VERSION "0.1"

NS_ :

BS_ :

BU_ : bms_lv dash dspace sens_front sens_rear tlb_bat

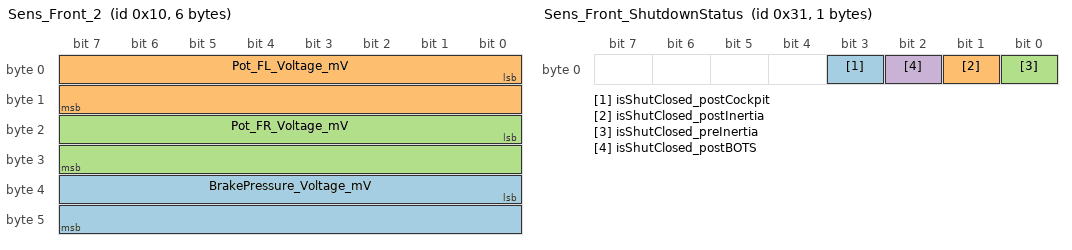
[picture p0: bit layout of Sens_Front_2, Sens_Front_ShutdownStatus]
BO_ 16 Sens_Front_2: 6 Vector__XXX
	SG_ BrakePressure_Voltage_mV : 32|16@1+ (1,0) [0|65535] "" Vector__XXX
	SG_ Pot_FL_Voltage_mV : 0|16@1+ (1,0) [0|65535] "" Vector__XXX
	SG_ Pot_FR_Voltage_mV : 16|16@1+ (1,0) [0|65535] "" Vector__XXX

BO_ 49 Sens_Front_ShutdownStatus: 1 Vector__XXX
	SG_ isShutClosed_postCockpit : 3|1@1- (1,0) [0|1] "" Vector__XXX
	SG_ isShutClosed_postInertia : 1|1@1- (1,0) [0|1] "" Vector__XXX
	SG_ isShutClosed_preInertia : 0|1@1- (1,0) [0|1] "" Vector__XXX
	SG_ isShutClosed_postBOTS : 2|1@1- (1,0) [0|1] "" Vector__XXX

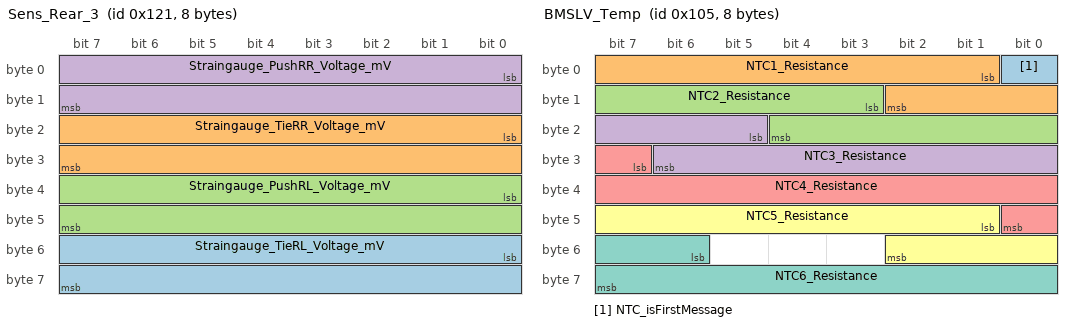
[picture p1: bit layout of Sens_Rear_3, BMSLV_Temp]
BO_ 289 Sens_Rear_3: 8 Vector__XXX
	SG_ Straingauge_TieRL_Voltage_mV : 48|16@1+ (1,0) [0|65535] "" Vector__XXX
	SG_ Straingauge_TieRR_Voltage_mV : 16|16@1+ (1,0) [0|65535] "" Vector__XXX
	SG_ Straingauge_PushRL_Voltage_mV : 32|16@1+ (1,0) [0|65535] "" Vector__XXX
	SG_ Straingauge_PushRR_Voltage_mV : 0|16@1+ (1,0) [0|65535] "" Vector__XXX

BO_ 258 BMSLV_BatteryPackGeneral: 4 Vector__XXX
	SG_ Current_Sensor_Voltage : 0|16@1+ (0.076,0) [0|4980.66] "" Vector__XXX
	SG_ LV_Total_Voltage_mV : 16|16@1+ (0.267,14000) [14000|31497.8] "" Vector__XXX

BO_ 261 BMSLV_Temp: 8 Vector__XXX
	SG_ NTC_isFirstMessage : 0|1@1- (1,0) [0|1] "" Vector__XXX
	SG_ NTC1_Resistance : 1|10@1+ (31.25,1000) [1000|32968.8] "" Vector__XXX
	SG_ NTC2_Resistance : 11|10@1+ (31.25,1000) [1000|32968.8] "" Vector__XXX
	SG_ NTC3_Resistance : 21|10@1+ (31.25,1000) [1000|32968.8] "" Vector__XXX
	SG_ NTC4_Resistance : 31|10@1+ (31.25,1000) [1000|32968.8] "" Vector__XXX
	SG_ NTC5_Resistance : 41|10@1+ (31.25,1000) [1000|32968.8] "" Vector__XXX
	SG_ NTC6_Resistance : 54|10@1+ (31.25,1000) [1000|32968.8] "" Vector__XXX

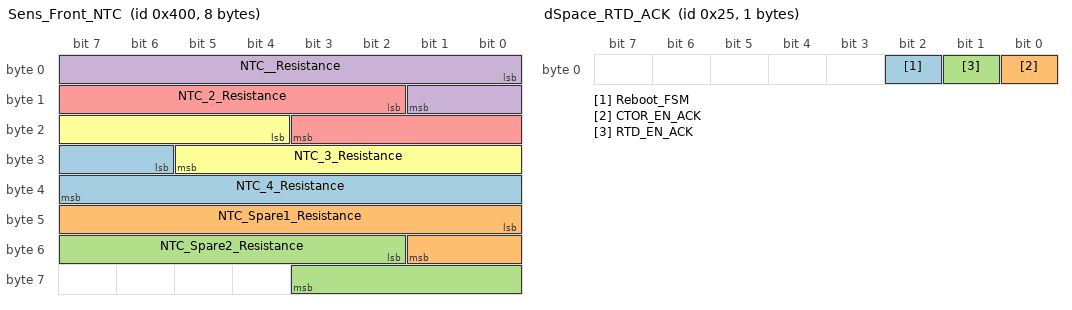
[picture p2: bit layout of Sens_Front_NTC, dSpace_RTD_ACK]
BO_ 1024 Sens_Front_NTC: 8 Vector__XXX
	SG_ NTC_4_Resistance : 30|10@1+ (1,0) [0|1023] "" Vector__XXX
	SG_ NTC_Spare1_Resistance : 40|10@1+ (1,0) [0|1023] "" Vector__XXX
	SG_ NTC_Spare2_Resistance : 50|10@1+ (1,0) [0|1023] "" Vector__XXX
	SG_ NTC__Resistance : 0|10@1+ (1,0) [0|1023] "" Vector__XXX
	SG_ NTC_2_Resistance : 10|10@1+ (1,0) [0|1023] "" Vector__XXX
	SG_ NTC_3_Resistance : 20|10@1+ (1,0) [0|1023] "" Vector__XXX

BO_ 38 Steering_RTD: 1 Vector__XXX
	SG_ RTD_CMD : 0|8@1+ (1,0) [0|255] "" Vector__XXX

BO_ 37 dSpace_RTD_ACK: 1 Vector__XXX
	SG_ Reboot_FSM : 2|1@1- (1,0) [0|1] "" Vector__XXX
	SG_ CTOR_EN_ACK : 0|1@1- (1,0) [0|1] "" Vector__XXX
	SG_ RTD_EN_ACK : 1|1@1- (1,0) [0|1] "" Vector__XXX

BO_ 259 BMSLV_Status: 2 Vector__XXX
	SG_ isRelayOpen : 0|1@1- (1,0) [0|1] "" Vector__XXX
	SG_ BMSLV_StatusMessage : 1|8@1+ (1,0) [0|255] "" Vector__XXX

BO_ 70 TlbBatIntSig: 8 tlb_bat
	SG_ DcBusPrchRlyEnAuxState : 24|2@1+ (1,0) [0|1] "" dspace
	SG_ DcBusVehSideOver60VImpErr : 32|2@1+ (1,0) [0|1] "" dspace
	SG_ DcBusPrchRlyEnIntState : 18|2@1+ (1,0) [0|1] "" dspace
	SG_ ImdErrLtch : 2|2@1+ (1,0) [0|1] "" dspace
	SG_ ShtdwnPrchRlyEn : 4|2@1+ (1,0) [0|1] "" dspace
	SG_ Shrt2GndAirNeg : 6|2@1+ (1,0) [0|1] "" dspace
	SG_ Shrt2GndAir : 10|2@1+ (1,0) [0|1] "" dspace
	SG_ AirPosClsdIntState : 16|2@1+ (1,0) [0|1] "" dspace
	SG_ DcBusPrchRlyEnImpErr : 30|2@1+ (1,0) [0|1] "" dspace
	SG_ AnyImpErr : 34|2@1+ (1,0) [0|1] "" dspace
	SG_ AmsErrLtch : 0|2@1+ (1,0) [0|1] "" dspace
	SG_ TsalGreenEnActiveLevel : 38|2@1+ (1,0) [0|1] "" dspace
	SG_ AnyImpErrLtch : 36|2@1+ (1,0) [0|1] "" dspace
	SG_ AirNegClsdIntState : 14|2@1+ (1,0) [0|1] "" dspace
	SG_ AirPosClsdAuxState : 22|2@1+ (1,0) [0|1] "" dspace
	SG_ AirNegClsdImpErr : 26|2@1+ (1,0) [0|1] "" dspace
	SG_ DcBusVehicleSideOver60V : 12|2@1+ (1,0) [0|1] "" dspace
	SG_ AirNegClsdAuxState : 20|2@1+ (1,0) [0|1] "" dspace
	SG_ AirPosClsdImpErr : 28|2@1+ (1,0) [0|1] "" dspace
	SG_ Shrt2GndAirPos : 8|2@1+ (1,0) [0|1] "" dspace

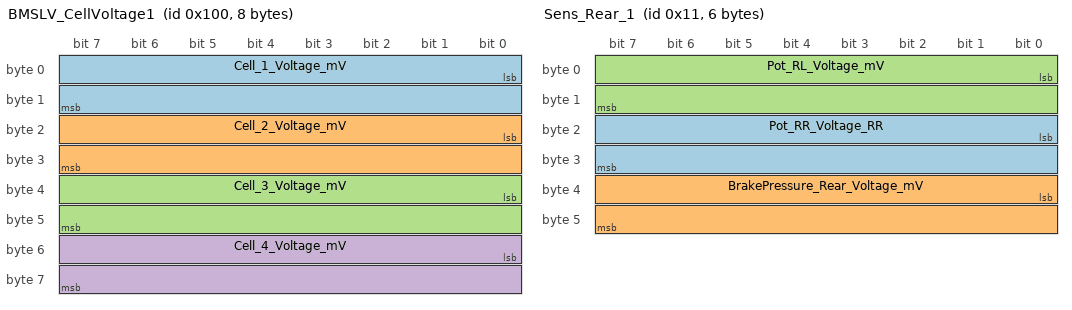
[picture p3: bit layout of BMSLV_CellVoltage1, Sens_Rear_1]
BO_ 256 BMSLV_CellVoltage1: 8 Vector__XXX
	SG_ Cell_1_Voltage_mV : 0|16@1+ (0.038,2000) [2000|4490.33] "" Vector__XXX
	SG_ Cell_2_Voltage_mV : 16|16@1+ (0.038,2000) [2000|4490.33] "" Vector__XXX
	SG_ Cell_3_Voltage_mV : 32|16@1+ (0.038,2000) [2000|4490.33] "" Vector__XXX
	SG_ Cell_4_Voltage_mV : 48|16@1+ (0.038,2000) [2000|4490.33] "" Vector__XXX

BO_ 17 Sens_Rear_1: 6 Vector__XXX
	SG_ Pot_RR_Voltage_RR : 16|16@1+ (1,0) [0|65535] "" Vector__XXX
	SG_ BrakePressure_Rear_Voltage_mV : 32|16@1+ (1,0) [0|65535] "" Vector__XXX
	SG_ Pot_RL_Voltage_mV : 0|16@1+ (1,0) [0|65535] "" Vector__XXX

BO_ 1026 Sens_Rear_2: 4 Vector__XXX
	SG_ CoolingPressure_DX_Voltage_mV : 0|16@1+ (1,0) [0|65535] "" Vector__XXX
	SG_ CoolingPressure_SX_Voltage_mV : 16|16@1+ (1,0) [0|65535] "" Vector__XXX

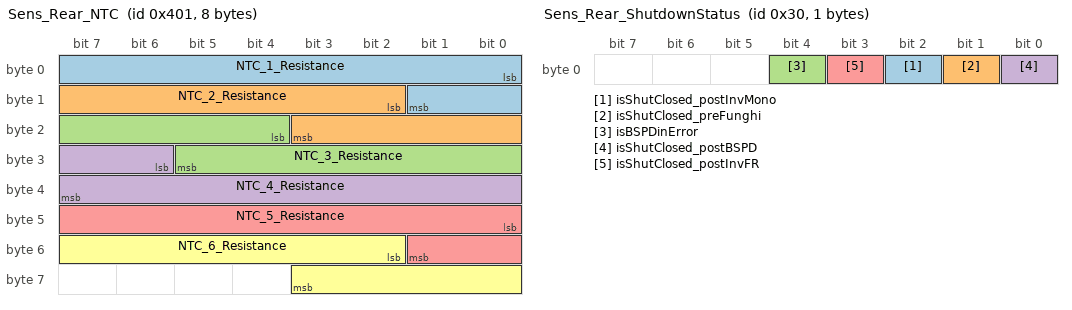
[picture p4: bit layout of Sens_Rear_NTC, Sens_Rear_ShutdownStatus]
BO_ 1025 Sens_Rear_NTC: 8 Vector__XXX
	SG_ NTC_1_Resistance : 0|10@1+ (1,0) [0|1023] "" Vector__XXX
	SG_ NTC_2_Resistance : 10|10@1+ (1,0) [0|1023] "" Vector__XXX
	SG_ NTC_3_Resistance : 20|10@1+ (1,0) [0|1023] "" Vector__XXX
	SG_ NTC_4_Resistance : 30|10@1+ (1,0) [0|1023] "" Vector__XXX
	SG_ NTC_5_Resistance : 40|10@1+ (1,0) [0|1023] "" Vector__XXX
	SG_ NTC_6_Resistance : 50|10@1+ (1,0) [0|1023] "" Vector__XXX

BO_ 48 Sens_Rear_ShutdownStatus: 1 Vector__XXX
	SG_ isShutClosed_postInvMono : 2|1@1- (1,0) [0|1] "" Vector__XXX
	SG_ isShutClosed_preFunghi : 1|1@1- (1,0) [0|1] "" Vector__XXX
	SG_ isBSPDinError : 4|1@1- (1,0) [0|1] "" Vector__XXX
	SG_ isShutClosed_postBSPD : 0|1@1- (1,0) [0|1] "" Vector__XXX
	SG_ isShutClosed_postInvFR : 3|1@1- (1,0) [0|1] "" Vector__XXX

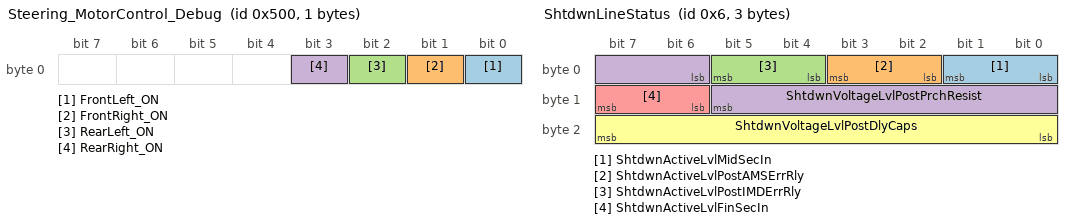
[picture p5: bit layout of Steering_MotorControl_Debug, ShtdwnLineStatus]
BO_ 1280 Steering_MotorControl_Debug: 1 Vector__XXX
	SG_ FrontLeft_ON : 0|1@1- (1,0) [0|1] "" Vector__XXX
	SG_ FrontRight_ON : 1|1@1- (1,0) [0|1] "" Vector__XXX
	SG_ RearLeft_ON : 2|1@1- (1,0) [0|1] "" Vector__XXX
	SG_ RearRight_ON : 3|1@1- (1,0) [0|1] "" Vector__XXX

BO_ 6 ShtdwnLineStatus: 3 tlb_bat
	SG_ ShtdwnActiveLvlMidSecIn : 0|2@1+ (1,0) [0|1] "" dspace
	SG_ ShtdwnActiveLvlPostAMSErrRly : 2|2@1+ (1,0) [0|1] "" dspace
	SG_ ShtdwnActiveLvlPostIMDErrRly : 4|2@1+ (1,0) [0|1] "" dspace
	SG_ ShtdwnVoltageLvlPostPrchResist : 6|8@1+ (0.119,0) [0|30] "" dspace
	SG_ ShtdwnActiveLvlFinSecIn : 14|2@1+ (1,0) [0|1] "" dspace
	SG_ ShtdwnVoltageLvlPostDlyCaps : 16|8@1+ (0.119,0) [0|30] "" dspace

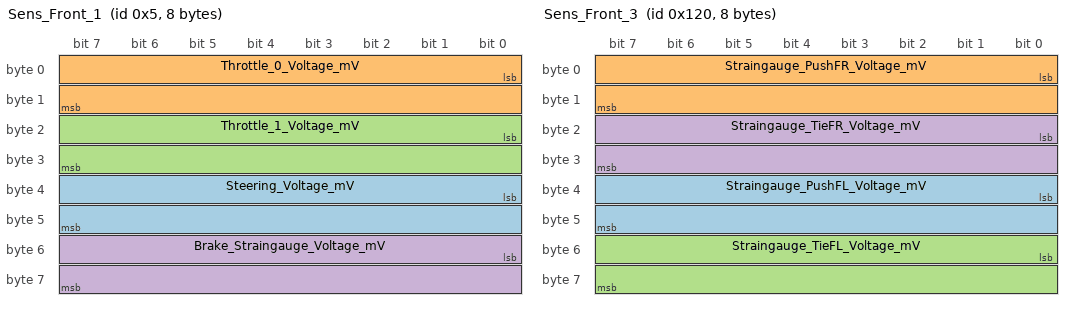
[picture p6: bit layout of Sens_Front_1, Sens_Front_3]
BO_ 5 Sens_Front_1: 8 Vector__XXX
	SG_ Steering_Voltage_mV : 32|16@1+ (1,0) [0|65535] "" Vector__XXX
	SG_ Throttle_0_Voltage_mV : 0|16@1+ (1,0) [0|65535] "" Vector__XXX
	SG_ Throttle_1_Voltage_mV : 16|16@1+ (1,0) [0|65535] "" Vector__XXX
	SG_ Brake_Straingauge_Voltage_mV : 48|16@1+ (1,0) [0|65535] "" Vector__XXX

BO_ 288 Sens_Front_3: 8 Vector__XXX
	SG_ Straingauge_PushFL_Voltage_mV : 32|16@1+ (1,0) [0|65535] "" Vector__XXX
	SG_ Straingauge_PushFR_Voltage_mV : 0|16@1+ (1,0) [0|65535] "" Vector__XXX
	SG_ Straingauge_TieFL_Voltage_mV : 48|16@1+ (1,0) [0|65535] "" Vector__XXX
	SG_ Straingauge_TieFR_Voltage_mV : 16|16@1+ (1,0) [0|65535] "" Vector__XXX

BO_ 7 TLB_Battery_TSALStatus: 4 Vector__XXX
	SG_ Implausibility_isAnyImp_Latched : 29|1@1- (1,0) [0|1] "" Vector__XXX
	SG_ TSAL_isAIRPosClosed : 1|1@1- (1,0) [0|1] "" Vector__XXX
	SG_ Implausibility_isAIRNegImp_Present : 26|1@1- (1,0) [0|1] "" Vector__XXX
	SG_ TSAL_IsAIRNegClosed : 2|1@1- (1,0) [0|1] "" Vector__XXX
	SG_ TSAL_IsRelayPrechargeClosed : 3|1@1- (1,0) [0|1] "" Vector__XXX
	SG_ Implausibility_isRelayPrechargeImp_Present : 27|1@1- (1,0) [0|1] "" Vector__XXX
	SG_ IntentionalState_AIRPos : 8|1@1- (1,0) [0|1] "" Vector__XXX
	SG_ IntentionalState_RelayPrecharge : 10|1@1- (1,0) [0|1] "" Vector__XXX
	SG_ SCS_Short2GND_AirPos : 16|1@1- (1,0) [0|1] "" Vector__XXX
	SG_ SCS_isAnyShort2GND_Present : 19|1@1- (1,0) [0|1] "" Vector__XXX
	SG_ TSAL_isDCBusOver60V : 4|1@1- (1,0) [0|1] "" Vector__XXX
	SG_ TSAL_isGreenON : 0|1@1- (1,0) [0|1] "" Vector__XXX
	SG_ Implausibility_isAIRPosImp_Present : 25|1@1- (1,0) [0|1] "" Vector__XXX
	SG_ Implausibility_isAnyImp_Present : 24|1@1- (1,0) [0|1] "" Vector__XXX
	SG_ Implausibility_isDCBusVoltageImp_Present : 28|1@1- (1,0) [0|1] "" Vector__XXX
	SG_ IntentionalState_AIRNeg : 9|1@1- (1,0) [0|1] "" Vector__XXX
	SG_ SCS_Short2GND_AirNeg : 17|1@1- (1,0) [0|1] "" Vector__XXX

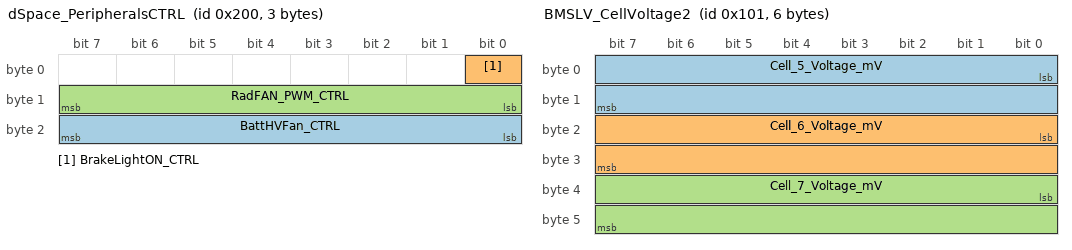
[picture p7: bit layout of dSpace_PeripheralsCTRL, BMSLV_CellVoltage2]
BO_ 512 dSpace_PeripheralsCTRL: 3 Vector__XXX
	SG_ BattHVFan_CTRL : 16|8@1+ (1,0) [0|255] "" Vector__XXX
	SG_ BrakeLightON_CTRL : 0|1@1- (1,0) [0|1] "" Vector__XXX
	SG_ RadFAN_PWM_CTRL : 8|8@1+ (1,0) [0|255] "" Vector__XXX

BO_ 257 BMSLV_CellVoltage2: 6 Vector__XXX
	SG_ Cell_5_Voltage_mV : 0|16@1+ (0.038,2000) [2000|4490.33] "" Vector__XXX
	SG_ Cell_6_Voltage_mV : 16|16@1+ (0.038,2000) [2000|4490.33] "" Vector__XXX
	SG_ Cell_7_Voltage_mV : 32|16@1+ (1,0) [0|65535] "" Vector__XXX

CM_ BU_ sens_rear "sensorboard rear ECU" ;
CM_ BU_ tlb_bat "tsal-latch-board battery ECU" ;
CM_ BU_ bms_lv "battery-management-system low-voltage" ;
CM_ BU_ dash "dashboard ECU" ;
CM_ BU_ dspace "automotive ECU" ;
CM_ BU_ sens_front "sensorboard front ECU" ;
CM_ BO_ 70 "tlb battery internal functions" ;
CM_ SG_ 70 DcBusVehicleSideOver60V "High Voltage DC Bus, vehicle side (@ Air Positive), over 60 volt" ;
CM_ SG_ 70 AirNegClsdIntState "AIR negative closed, Intentional State (signal is reliant on shutdown line beeing active)" ;
CM_ SG_ 70 AirPosClsdAuxState "AIR positive closed, auxiliary/actual state (signal is reliant on shutdown line beegin active)" ;
CM_ SG_ 70 AirNegClsdImpErr "AIR negative closed implausibility error active (Intentional State != Auxiliary State)" ;
CM_ SG_ 70 Shrt2GndAirPos "Shortcircuit to GND detected on AIR positive terminal" ;
CM_ SG_ 70 AirNegClsdAuxState "AIR negative closed, auxiliary/actual state (signal is reliant on shutdown line beegin active)" ;
CM_ SG_ 70 AirPosClsdImpErr "AIR positive closed implausibility error active (Intentional State != Auxiliary State)" ;
CM_ SG_ 70 DcBusPrchRlyEnIntState "High Voltage DC bus precharge relay enable, intentional state (signal is reliant on shutdown line beeing active)" ;
CM_ SG_ 70 DcBusPrchRlyEnAuxState "High Voltage DC bus precharge relay enable, auxiliary/actual state (signal is reliant on shutdown line beeing active)" ;
CM_ SG_ 70 DcBusVehSideOver60VImpErr "High Voltage DC Bus, vehicle side (@ Air Positive), over 60 volt, implausibility error active (more then 60V but can't be SUPER DANGER)" ;
CM_ SG_ 70 DcBusPrchRlyEnImpErr "High Voltage DC bus precharge relay enable, implausibility error active (Intentional State != Auxiliary State)" ;
CM_ SG_ 70 AnyImpErr "An/Any implausibility error is active" ;
CM_ SG_ 70 AmsErrLtch "AMS error latched active, disables AMS Error Relay" ;
CM_ SG_ 70 ImdErrLtch "IMD error latched active, disables IMD Error Relay" ;
CM_ SG_ 70 ShtdwnPrchRlyEn "Shutdown Precharge Relay Enable status, enables Shutdwon Precharge Relay" ;
CM_ SG_ 70 Shrt2GndAirNeg "Shortcircuit to GND detected on AIR negative terminal" ;
CM_ SG_ 70 Shrt2GndAir "Shortcircuit to GND detected on an AIR terminal (either poisitive or negative)" ;
CM_ SG_ 70 AirPosClsdIntState "AIR positive closed, Intentional State (signal is reliant on shutdown line beeing active)" ;
CM_ SG_ 70 AnyImpErrLtch "An/Any implausibility error is active, latched value" ;
CM_ SG_ 70 TsalGreenEnActiveLevel "TSAL green enable active level" ;
CM_ BO_ 6 "shutdown line status" ;
CM_ SG_ 6 ShtdwnVoltageLvlPostDlyCaps "Shutdown line voltage level post delay capacitors of shutdown line" ;
CM_ SG_ 6 ShtdwnActiveLvlMidSecIn "Shutdown line active level @ middle section input" ;
CM_ SG_ 6 ShtdwnActiveLvlPostAMSErrRly "Shutdown line active level post AMS error relay" ;
CM_ SG_ 6 ShtdwnActiveLvlPostIMDErrRly "Shutdown line active level post IMD error relay" ;
CM_ SG_ 6 ShtdwnVoltageLvlPostPrchResist "Shutdown line voltage level post precharge resistor of shutdown line" ;
CM_ SG_ 6 ShtdwnActiveLvlFinSecIn "Shutdown line active level @ final section input" ;

BA_DEF_ BO_ "GenMsgBackgroundColor" STRING "" ;
BA_DEF_ BO_ "GenMsgForegroundColor" STRING "" ;
BA_DEF_DEF_ "GenMsgBackgroundColor" "#ffffff" ;
BA_DEF_DEF_ "GenMsgForegroundColor" "#000000" ;
